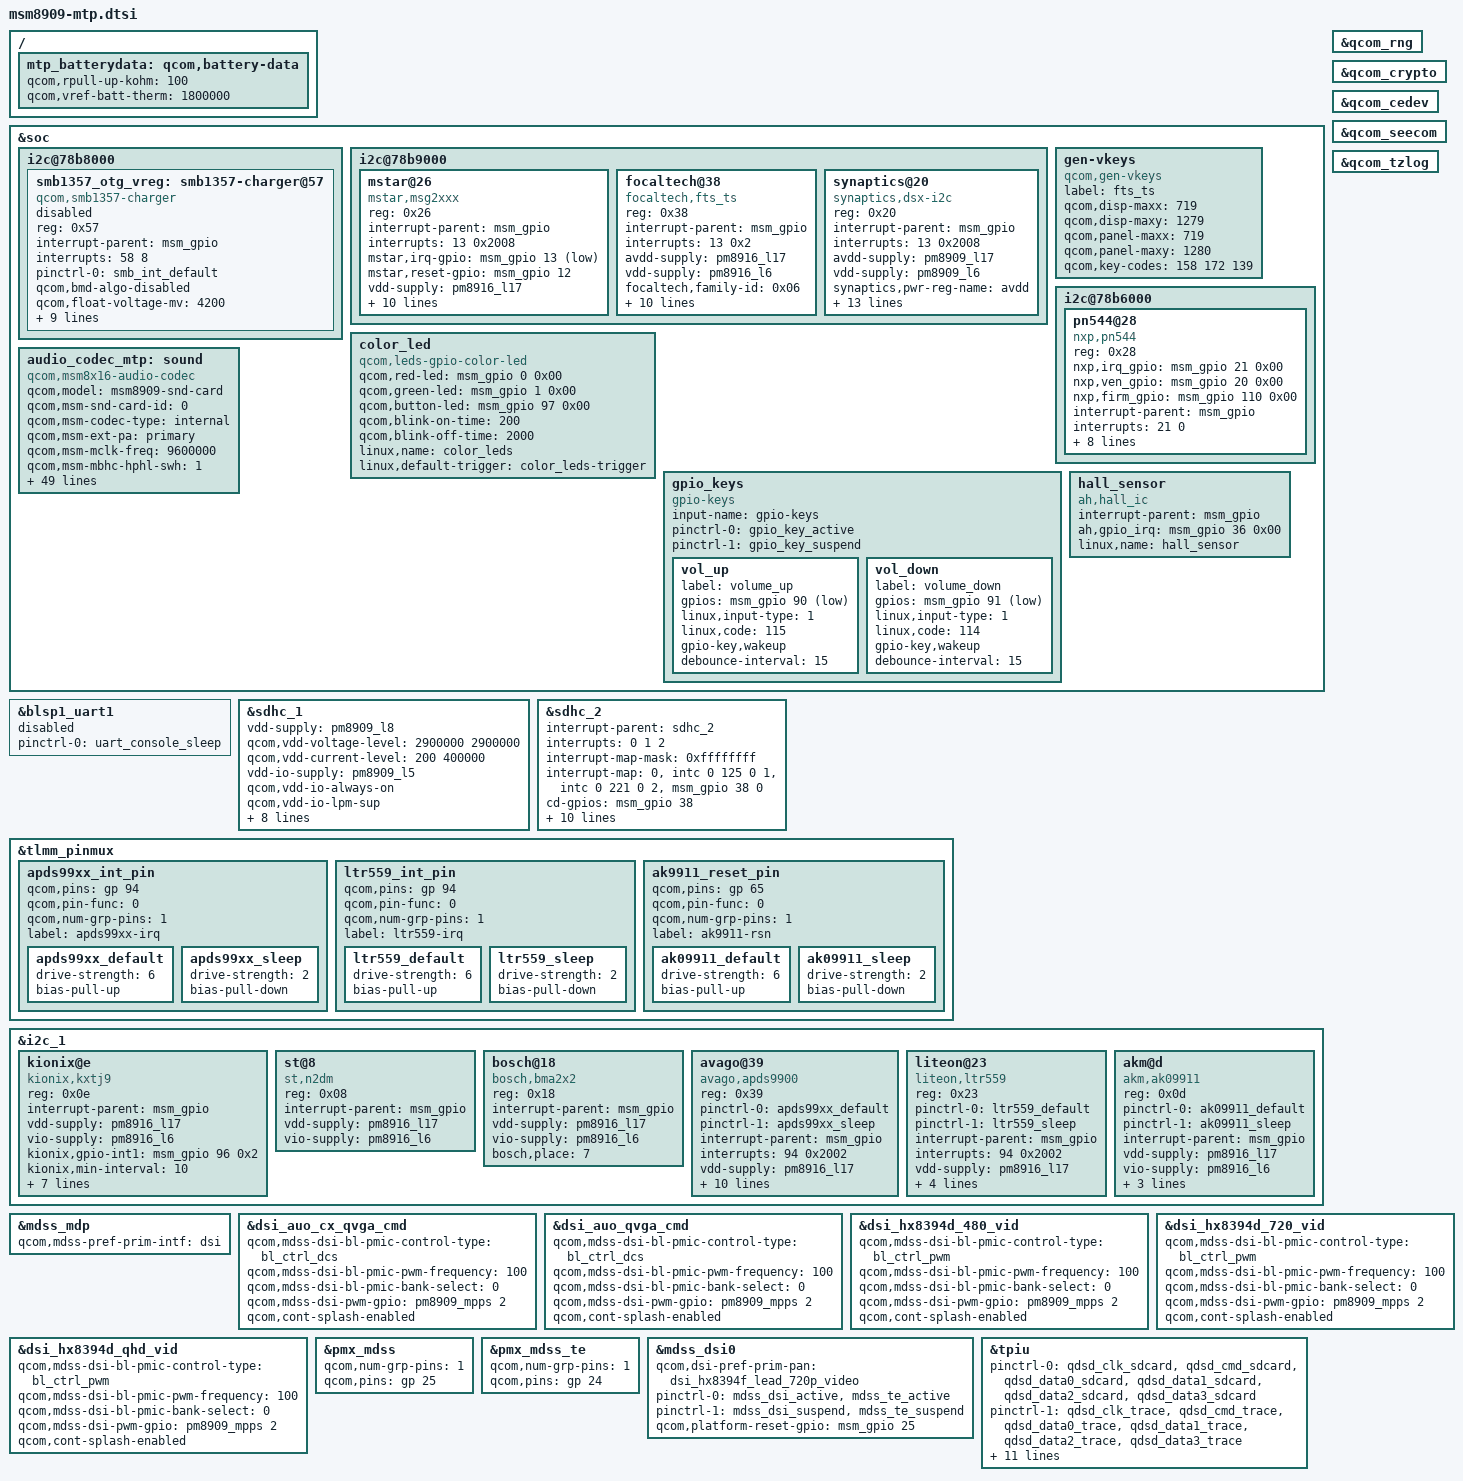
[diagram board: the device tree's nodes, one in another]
/* Copyright (c) 2014-2015, The Linux Foundation. All rights reserved.
 *
 * This program is free software; you can redistribute it and/or modify
 * it under the terms of the GNU General Public License version 2 and
 * only version 2 as published by the Free Software Foundation.
 *
 * This program is distributed in the hope that it will be useful,
 * but WITHOUT ANY WARRANTY; without even the implied warranty of
 * MERCHANTABILITY or FITNESS FOR A PARTICULAR PURPOSE.  See the
 * GNU General Public License for more details.
 */

#include "msm8909.dtsi"
#include "msm8909-pinctrl.dtsi"
#include "msm8909-camera-sensor-mtp.dtsi"
#include "msm8909-pm8916.dtsi"


&soc {
	/*
	 * DT node to add support for SMB135x charger and integrate
	 * with VM-BMS.
	 */
	i2c@78b8000 {
		smb1357_otg_vreg: smb1357-charger@57 {
			compatible = "qcom,smb1357-charger";
			reg = <0x57>;
			interrupt-parent = <&msm_gpio>;
			interrupts = <58 8>;
			pinctrl-names = "default";
			pinctrl-0 = <&smb_int_default>;

			qcom,bmd-algo-disabled;
			qcom,float-voltage-mv = <4200>;
			qcom,charging-timeout = <1536>;
			qcom,recharge-thresh-mv = <100>;
			regulator-name = "smb1357_otg_vreg";
			qcom,soft-vfloat-comp-disabled;
			qcom,thermal-mitigation = <1500 700 600 0>;

			qcom,bms-psy-name = "bms";

			/*
			 * Disable SMB1357 based charging termination as BMS
			 * controls charging.
			 */
			qcom,iterm-disabled;

			/*
			 * Disable charge inhibit feature to start chargin on
			 * charger insertion independent of battery voltage.
			 */
			qcom,inhibit-disabled;

			/* BMS is controlling charging/re-charge */
			qcom,bms-controlled-charging;

			/*
			 * To enable charger node:
			 * set status = "ok" and
			 * add 'qcom,use-external-charger' to pm8909_chg node
			 */
			status = "disabled";
		};
	};

	i2c@78b9000 { /* BLSP1 QUP5 */
	    mstar@26 { /*ZTE_MODIFY */
			compatible = "mstar,msg2xxx";
			reg = <0x26>;
			interrupt-parent = <&msm_gpio>;
			interrupts = <13 0x2008>;
			mstar,irq-gpio = <&msm_gpio 13 0x00000001>;
			mstar,reset-gpio = <&msm_gpio 12 0x0>;
			vdd-supply = <&pm8916_l17>;
			vcc_i2c-supply = <&pm8916_l6>;
			mstar,display-coords = <0 0 480 854>;
			pinctrl-names = "pmx_ts_active","pmx_ts_suspend","pmx_ts_release";
			pinctrl-0 = <&ts_int_active &ts_reset_active>;
			pinctrl-1 = <&ts_int_suspend &ts_reset_suspend>;
			pinctrl-2 = <&ts_release>;
			mstar,button-map = <158 172 139>;
			mstar,ic-type = <2>;
			mstar,num-max-touches = <5>;
			mstar,hard-reset-delay-ms = <100>;
			mstar,post-hard-reset-delay-ms = <100>;
		};
		focaltech@38{
			compatible = "focaltech,fts_ts";
			reg = <0x38>;
			interrupt-parent = <&msm_gpio>;
			interrupts = <13 0x2>;
			avdd-supply = <&pm8916_l17>;
			vdd-supply = <&pm8916_l6>;
			focaltech,family-id = <0x06>;
			focaltech,reset-gpio = <&msm_gpio 12 0x00>;
			focaltech,irq-gpio = <&msm_gpio 13 0x00>;
			focaltech,display-coords = <0 0 720 1280>;
			focaltech,panel-coords = <0 0 720 1280>;
			focaltech,button-map= <158 172 139>;
			focaltech,hard-reset-delay-ms = <20>;
			focaltech,soft-reset-delay-ms = <150>;
			focaltech,num-max-touches = <10>;
			focaltech,no-force-update;
			focaltech,i2c-pull-up;
		};

		synaptics@20 {
			compatible = "synaptics,dsx-i2c";
			reg = <0x20>;
			interrupt-parent = <&msm_gpio>;
			interrupts = <13 0x2008>;
			avdd-supply = <&pm8909_l17>;
			vdd-supply = <&pm8909_l6>;
			synaptics,pwr-reg-name = "avdd";
			synaptics,bus-reg-name = "vdd";
			synaptics,irq-gpio = <&msm_gpio 13 0x2008>;
			synaptics,reset-gpio = <&msm_gpio 12 0x0>;
			synaptics,irq-on-state = <0>;
			synaptics,irq-flags = <0x2008>; /* IRQF_ONESHOT | IRQF_TRIGGER_LOW */
			synaptics,power-delay-ms = <200>;
			synaptics,reset-delay-ms = <200>;
			synaptics,reset-on-state = <0>;
			synaptics,reset-active-ms = <20>;
			synaptics,display-coords = <0 0 719 1279>;
			synaptics,panel-coords = <0 0 719 1280>;
			synaptics,button-map = <139 172 158>;
			/* uncomment and update line below as appropriate if there are 0D buttons */
			synaptics,cap-button-codes = <139 172 158>;
			/* uncomment and update lines below as appropriate if there are virtual buttons */
			/* synaptics,vir-button-codes = <102 100 900 100 60 158 300 900 100 60>; */
			/* synaptics,max-y-for-2d = <800>; */
		};
	};

	gen-vkeys {
		compatible = "qcom,gen-vkeys";
		label = "synaptics_dsx";
		qcom,disp-maxx = <719>;
		qcom,disp-maxy = <1279>;
		qcom,panel-maxx = <719>;
		qcom,panel-maxy = <1280>;
		qcom,key-codes = <158 172 139>;
	};
    gen-vkeys {
		compatible = "qcom,gen-vkeys";
		label = "fts_ts";
		qcom,disp-maxx = <719>;
		qcom,disp-maxy = <1279>;
		qcom,panel-maxx = <719>;
		qcom,panel-maxy = <1280>;
		qcom,key-codes = <158 172 139>;
	};

	i2c@78b6000 { /* BLSP1 QUP2 */
	//	nfc-nci@e {
	//		compatible = "qcom,nfc-nci";
	//		reg = <0x0e>;
	//		qcom,irq-gpio = <&msm_gpio 21 0x00>;
	//		qcom,dis-gpio = <&msm_gpio 20 0x00>;
	//		qcom,clk-src = "BBCLK2";
	//		interrupt-parent = <&msm_gpio>;
	//		interrupts = <21 0>;
	//		interrupt-names = "nfc_irq";
	//		pinctrl-names = "nfc_active","nfc_suspend";
	//		pinctrl-0 = <&nfc_int_active &nfc_disable_active>;
	//		pinctrl-1 = <&nfc_int_suspend &nfc_disable_suspend>;
	//		qcom,clk-gpio = <&pm8909_gpios 2 0>;
	//		clocks = <&clock_rpm clk_bb_clk2_pin>;
	//		clock-names = "ref_clk";
	//	};
		pn544@28 {
			compatible = "nxp,pn544";
			reg = <0x28>;
			nxp,irq_gpio = <&msm_gpio 21 0x00>;
			nxp,ven_gpio = <&msm_gpio 20 0x00>;
			nxp,firm_gpio = <&msm_gpio 110 0x00>;
			interrupt-parent = <&msm_gpio>;
			interrupts = <21 0>;
			interrupt-names = "nfc_irq";
			pinctrl-names = "nfc_active","nfc_suspend";
			pinctrl-0 = <&nfc_int_active &nfc_disable_active &nfc_download_active>;
			pinctrl-1 = <&nfc_int_suspend &nfc_disable_suspend &nfc_download_suspend>;
			nxp,clk-src = "BBCLK2";
			nxp,clk-gpio = <&pm8916_gpios 2 0>;
			clocks = <&clock_rpm clk_bb_clk2_pin>;
			clock-names = "ref_clk";
			vdd-supply = <&pm8916_l5>;
		};
	};
/*chenyingfang 20150924 for color_led,start*/
	color_led {
		compatible = "qcom,leds-gpio-color-led";
		status = "okay";
		qcom,red-led = <&msm_gpio 0 0x00>;
		qcom,green-led = <&msm_gpio 1 0x00>;
		qcom,button-led = <&msm_gpio 97 0x00>;
		qcom,blink-on-time = <200>;
		qcom,blink-off-time = <2000>;
		linux,name = "color_leds";
		linux,default-trigger = "color_leds-trigger";
	};
/*chenyingfang 20150924 for color_led,end*/
	gpio_keys {
		compatible = "gpio-keys";
		input-name = "gpio-keys";
		pinctrl-names = "tlmm_gpio_key_active","tlmm_gpio_key_suspend";
		pinctrl-0 = <&gpio_key_active>;
		pinctrl-1 = <&gpio_key_suspend>;

        /* ZTE_MODIFY start by dingli10091962
		camera_focus {
			label = "camera_focus";
			gpios = <&msm_gpio 91 0x1>;
			linux,input-type = <1>;
			linux,code = <0x210>;
			gpio-key,wakeup;
			debounce-interval = <15>;
		};

		camera_snapshot {
			label = "camera_snapshot";
			gpios = <&msm_gpio 92 0x1>;
			linux,input-type = <1>;
			linux,code = <0x2fe>;
			gpio-key,wakeup;
			debounce-interval = <15>;
		};
        ZTE_MODIFY end by dingli10091962 */
        
		vol_up {
			label = "volume_up";
			gpios = <&msm_gpio 90 0x1>;
			linux,input-type = <1>;
			linux,code = <115>;
			gpio-key,wakeup;
			debounce-interval = <15>;
		};

		// ZTE_MODIFY start by dingli10091962
        vol_down {
			label = "volume_down";
			gpios = <&msm_gpio 91 0x1>;
			linux,input-type = <1>;
			linux,code = <114>;
			gpio-key,wakeup;
			debounce-interval = <15>;
		};
        // ZTE_MODIFY end by dingli10091962        
	};

	audio_codec_mtp: sound {
		compatible = "qcom,msm8x16-audio-codec";
		qcom,model = "msm8909-snd-card";
		qcom,msm-snd-card-id = <0>;
		qcom,msm-codec-type = "internal";
		qcom,msm-ext-pa = "primary";
		qcom,msm-mclk-freq = <9600000>;
		qcom,msm-mbhc-hphl-swh = <1>;
		qcom,msm-mbhc-gnd-swh = <1>;
		qcom,msm-hs-micbias-type = "internal";
		//qcom,msm-micbias1-ext-cap;
		qcom,audio-routing =
			"RX_BIAS", "MCLK",
			"SPK_RX_BIAS", "MCLK",
			"INT_LDO_H", "MCLK",
			"MIC BIAS External", "Handset Mic",
			"MIC BIAS Internal2", "Headset Mic",
			"MIC BIAS External", "Secondary Mic",
			"AMIC1", "MIC BIAS External",
			"AMIC2", "MIC BIAS Internal2",
			"AMIC3", "MIC BIAS External";
		pinctrl-names = "cdc_lines_act",
				"cdc_lines_sus",
				"cross_conn_det_act",
				"cross_conn_det_sus";
		pinctrl-0 = <&cdc_pdm_lines_act>;
		pinctrl-1 = <&cdc_pdm_lines_sus>;
		pinctrl-2 = <&cross_conn_det_act>;
		pinctrl-3 = <&cross_conn_det_sus>;
		qcom,msm-spk-ext-pa = <&msm_gpio 95 0>;
		//qcom,cdc-us-euro-gpios = <&msm_gpio 97 0>;
		asoc-platform = <&pcm0>, <&pcm1>, <&voip>, <&voice>,
				<&loopback>, <&compress>, <&hostless>,
				<&afe>, <&lsm>, <&routing>, <&lpa>,
				<&voice_svc>;
		asoc-platform-names = "msm-pcm-dsp.0", "msm-pcm-dsp.1",
				"msm-voip-dsp", "msm-pcm-voice", "msm-pcm-loopback",
				"msm-compress-dsp", "msm-pcm-hostless", "msm-pcm-afe",
				"msm-lsm-client", "msm-pcm-routing", "msm-pcm-lpa",
				"msm-voice-svc";
		asoc-cpu = <&dai_pri_auxpcm>, <&dai_hdmi>,
				<&dai_mi2s0>, <&dai_mi2s1>, <&dai_mi2s2>, <&dai_mi2s3>,
				<&sb_0_rx>, <&sb_0_tx>, <&sb_1_rx>, <&sb_1_tx>,
				<&sb_3_rx>, <&sb_3_tx>, <&sb_4_rx>, <&sb_4_tx>,
				<&bt_sco_rx>, <&bt_sco_tx>,<&bt_a2dp_rx>,
                                <&int_fm_rx>, <&int_fm_tx>,
				<&afe_pcm_rx>, <&afe_pcm_tx>, <&afe_proxy_rx>, <&afe_proxy_tx>,
				<&incall_record_rx>, <&incall_record_tx>, <&incall_music_rx>,
				<&incall_music_2_rx>;
		asoc-cpu-names = "msm-dai-q6-auxpcm.1", "msm-dai-q6-hdmi.8",
				"msm-dai-q6-mi2s.0", "msm-dai-q6-mi2s.1",
				"msm-dai-q6-mi2s.2", "msm-dai-q6-mi2s.3",
				"msm-dai-q6-dev.16384", "msm-dai-q6-dev.16385",
				"msm-dai-q6-dev.16386", "msm-dai-q6-dev.16387",
				"msm-dai-q6-dev.16390", "msm-dai-q6-dev.16391",
				"msm-dai-q6-dev.16392", "msm-dai-q6-dev.16393",
				"msm-dai-q6-dev.12288", "msm-dai-q6-dev.12289",
				"msm-dai-q6-dev.12290", "msm-dai-q6-dev.12292",
                                "msm-dai-q6-dev.12293", "msm-dai-q6-dev.224",
				"msm-dai-q6-dev.225", "msm-dai-q6-dev.241",
				"msm-dai-q6-dev.240", "msm-dai-q6-dev.32771",
				"msm-dai-q6-dev.32772", "msm-dai-q6-dev.32773",
                                "msm-dai-q6-dev.32770";
		asoc-codec = <&stub_codec>, <&pm8909_conga_dig>;
		asoc-codec-names = "msm-stub-codec.1", "tombak_codec";
	};
};

&blsp1_uart1 {
	status = "disabled";
	pinctrl-names = "default";
	pinctrl-0 = <&uart_console_sleep>;
};

/ {
	mtp_batterydata: qcom,battery-data {
		qcom,rpull-up-kohm = <100>;
		qcom,vref-batt-therm = <1800000>;

		#include "batterydata-palladium.dtsi"
	};
};

&qcom_rng {
	status = "okay";
};

&qcom_crypto {
	status = "okay";
};

&qcom_cedev {
	status = "okay";
};

&qcom_seecom {
	status = "okay";
};

&qcom_tzlog {
	status = "okay";
};

&sdhc_1 {
	vdd-supply = <&pm8909_l8>;
	qcom,vdd-voltage-level = <2900000 2900000>;
	qcom,vdd-current-level = <200 400000>;

	vdd-io-supply = <&pm8909_l5>;
	qcom,vdd-io-always-on;
	qcom,vdd-io-lpm-sup;
	qcom,vdd-io-voltage-level = <1800000 1800000>;
	qcom,vdd-io-current-level = <200 60000>;

	pinctrl-names = "active", "sleep";
	pinctrl-0 = <&sdc1_clk_on &sdc1_cmd_on &sdc1_data_on>;
	pinctrl-1 = <&sdc1_clk_off &sdc1_cmd_off &sdc1_data_off>;

	qcom,bus-speed-mode = "HS200_1p8v", "DDR_1p8v";
	qcom,nonremovable;

	status = "ok";
};

&sdhc_2 {
	 #address-cells = <0>;
	interrupt-parent = <&sdhc_2>;
	interrupts = <0 1 2>;
	#interrupt-cells = <1>;
	interrupt-map-mask = <0xffffffff>;
	interrupt-map = <0 &intc 0 125 0
			1 &intc 0 221 0
			2 &msm_gpio 38 0>;
	interrupt-names = "hc_irq", "pwr_irq", "status_irq";
	// ZTE_MODIFY start by xiongping10053992 	
	cd-gpios = <&msm_gpio 38 0x0>;
	// ZTE_MODIFY end by xiongping10053992 	

	vdd-supply = <&pm8909_l11>;
	qcom,vdd-voltage-level = <1800000 2950000>;
	qcom,vdd-current-level = <15000 400000>;

	vdd-io-supply = <&pm8909_l12>;
	qcom,vdd-io-voltage-level = <1800000 2950000>;
	qcom,vdd-io-current-level = <200 50000>;

	pinctrl-names = "active", "sleep";
	pinctrl-0 = <&sdc2_clk_on &sdc2_cmd_on &sdc2_data_on &sdc2_cd_on>;
	pinctrl-1 = <&sdc2_clk_off &sdc2_cmd_off &sdc2_data_off &sdc2_cd_off>;

	status = "ok";
};

&tlmm_pinmux {
	apds99xx_int_pin {
		qcom,pins = <&gp 94>;
		qcom,pin-func = <0>;
		qcom,num-grp-pins = <1>;
		label = "apds99xx-irq";
		apds99xx_default: apds99xx_default {
			drive-strength = <6>;
			bias-pull-up;
		};
		apds99xx_sleep: apds99xx_sleep {
			drive-strength = <2>;
			bias-pull-down;
		};
	};

	    ltr559_int_pin {
		qcom,pins = <&gp 94>;
		qcom,pin-func = <0>;
		qcom,num-grp-pins = <1>;
		    label = "ltr559-irq";
		    ltr559_default: ltr559_default {
			drive-strength = <6>;
			bias-pull-up;
		};
		    ltr559_sleep: ltr559_sleep {
			drive-strength = <2>;
			bias-pull-down;
		};
	};
	ak9911_reset_pin {
		qcom,pins = <&gp 65>;
		qcom,pin-func = <0>;
		qcom,num-grp-pins = <1>;
		label = "ak9911-rsn";
		ak09911_default: ak09911_default {
			drive-strength = <6>;
			bias-pull-up;
		};
		ak09911_sleep: ak09911_sleep {
			drive-strength = <2>;
			bias-pull-down;
		};
	};
};

&i2c_1 { /* BLSP1 QUP1 */
	kionix@e {
		compatible = "kionix,kxtj9";
		reg = <0x0e>;
		interrupt-parent = <&msm_gpio>;
		vdd-supply = <&pm8916_l17>;
		vio-supply = <&pm8916_l6>;
		kionix,gpio-int1 = <&msm_gpio 96 0x2>;
		kionix,min-interval = <10>;
		kionix,init-interval = <100>;
		kionix,axis-map-x = <1>;
		kionix,axis-map-y = <0>;
		kionix,axis-map-z = <2>;
		kionix,g-range = <2>;
		kionix,res-12bit;
		//kionix,negate-x; 
		//kionix,negate-y;
		kionix,negate-z;
		}; 

	st@8 {
		compatible = "st,n2dm";
		reg = <0x08>;
		interrupt-parent = <&msm_gpio>;
		vdd-supply = <&pm8916_l17>;
		vio-supply = <&pm8916_l6>;
	};

	bosch@18 {
		compatible = "bosch,bma2x2";
		reg = <0x18>;
		interrupt-parent = <&msm_gpio>;
		vdd-supply = <&pm8916_l17>;
		vio-supply = <&pm8916_l6>;	
		bosch,place	 = <7>;
	};	

	avago@39 { /* Ambient light and proximity sensor */
		compatible = "avago,apds9900";
		reg = <0x39>;
		pinctrl-names = "default","sleep";
		pinctrl-0 = <&apds99xx_default>;
		pinctrl-1 = <&apds99xx_sleep>;
		interrupt-parent = <&msm_gpio>;
		interrupts = <94 0x2002>;
		vdd-supply = <&pm8916_l17>;
		vio-supply = <&pm8916_l6>;
		avago,irq-gpio = <&msm_gpio 94 0x2002>;
		//avago,ps-threshold = <600>;
		//avago,ps-hysteresis-threshold = <500>;
		avago,ps-threshold = <500>;
		avago,ps-hysteresis-threshold = <400>;
		avago,ps-pulse = <25>;
		avago,ps-pgain = <4>;
		avago,als-B = <186>;
		avago,als-C = <75>;
		avago,als-D = <129>;
		avago,ga-value = <256>;
	};

	    liteon@23 {
		    compatible = "liteon,ltr559";
		    reg = <0x23>;
		    pinctrl-names = "default","sleep";
		    pinctrl-0 = <&ltr559_default>;
		    pinctrl-1 = <&ltr559_sleep>;
			interrupt-parent = <&msm_gpio>;
		    interrupts = <94 0x2002>;
			vdd-supply = <&pm8916_l17>;
			vio-supply = <&pm8916_l6>;
		    liteon,intr = <&msm_gpio 94 0x2002>;
		    liteon,highthr = <300>;
		    liteon,lowthr = <200>;
	};


	akm@d {
		compatible = "akm,ak09911";
		reg = <0x0d>;	
		pinctrl-names = "ak09911_default", "ak09911_sleep";
		pinctrl-0 = <&ak09911_default>;
		pinctrl-1 = <&ak09911_sleep>;
		interrupt-parent = <&msm_gpio>;
		vdd-supply = <&pm8916_l17>;
		vio-supply = <&pm8916_l6>;
		akm,layout = <6>;
		akm,auto-report;
		akm,gpio_rstn = <&msm_gpio 65 0x00>;
	};
};

#include "dsi-panel-auo-qvga-cmd.dtsi"
#include "dsi-panel-auo-cx-qvga-cmd.dtsi"
#include "dsi-panel-hx8394d-480p-video.dtsi"
#include "dsi-panel-hx8394d-720p-video.dtsi"
#include "dsi-panel-hx8394d-qhd-video.dtsi"
#include "dsi-panel-hx8394f-lead-720p-video.dtsi"
#include "dsi-panel-hx8394f-yassy-720p-video.dtsi"
#include "dsi-panel-hx8394f-jdf-720p-video.dtsi"
#include "dsi-panel-nt35521-dijing-720p-video.dtsi"
&mdss_mdp {
	qcom,mdss-pref-prim-intf = "dsi";
};

&dsi_auo_cx_qvga_cmd {
        qcom,mdss-dsi-bl-pmic-control-type = "bl_ctrl_dcs";
        qcom,mdss-dsi-bl-pmic-pwm-frequency = <100>;
        qcom,mdss-dsi-bl-pmic-bank-select = <0>;
        qcom,mdss-dsi-pwm-gpio = <&pm8909_mpps 2 0>;
        qcom,cont-splash-enabled;
};

&dsi_auo_qvga_cmd {
        qcom,mdss-dsi-bl-pmic-control-type = "bl_ctrl_dcs";
        qcom,mdss-dsi-bl-pmic-pwm-frequency = <100>;
        qcom,mdss-dsi-bl-pmic-bank-select = <0>;
        qcom,mdss-dsi-pwm-gpio = <&pm8909_mpps 2 0>;
        qcom,cont-splash-enabled;
};

&dsi_hx8394d_480_vid {
        qcom,mdss-dsi-bl-pmic-control-type = "bl_ctrl_pwm";
        qcom,mdss-dsi-bl-pmic-pwm-frequency = <100>;
        qcom,mdss-dsi-bl-pmic-bank-select = <0>;
        qcom,mdss-dsi-pwm-gpio = <&pm8909_mpps 2 0>;
        qcom,cont-splash-enabled;
};

&dsi_hx8394d_720_vid {
	qcom,mdss-dsi-bl-pmic-control-type = "bl_ctrl_pwm";
	qcom,mdss-dsi-bl-pmic-pwm-frequency = <100>;
	qcom,mdss-dsi-bl-pmic-bank-select = <0>;
	qcom,mdss-dsi-pwm-gpio = <&pm8909_mpps 2 0>;
	qcom,cont-splash-enabled;
};

&dsi_hx8394d_qhd_vid {
	qcom,mdss-dsi-bl-pmic-control-type = "bl_ctrl_pwm";
	qcom,mdss-dsi-bl-pmic-pwm-frequency = <100>;
	qcom,mdss-dsi-bl-pmic-bank-select = <0>;
	qcom,mdss-dsi-pwm-gpio = <&pm8909_mpps 2 0>;
	qcom,cont-splash-enabled;
};

&pmx_mdss {
	//qcom,num-grp-pins = <2>;
	//qcom,pins = <&gp 25>, <&gp 37>;
	qcom,num-grp-pins = <1>;
	qcom,pins = <&gp 25>;
};

&pmx_mdss_te {
	qcom,num-grp-pins = <1>;
	qcom,pins = <&gp 24>;
};

&mdss_dsi0 {
	qcom,dsi-pref-prim-pan = <&dsi_hx8394f_lead_720p_video>;
	pinctrl-names = "mdss_default", "mdss_sleep";
	pinctrl-0 = <&mdss_dsi_active &mdss_te_active>;
	pinctrl-1 = <&mdss_dsi_suspend &mdss_te_suspend>;

	qcom,platform-reset-gpio = <&msm_gpio 25 0>;
	//qcom,platform-bklight-en-gpio = <&msm_gpio 37 0>;//modify by yujianhua no useful gpio
};

/* CoreSight */
&tpiu {
	pinctrl-names = "sdcard", "trace", "swduart",
			"swdtrc", "jtag", "spmi";
	/* NIDnT */
	pinctrl-0 = <&qdsd_clk_sdcard &qdsd_cmd_sdcard
		     &qdsd_data0_sdcard &qdsd_data1_sdcard
		     &qdsd_data2_sdcard &qdsd_data3_sdcard>;
	pinctrl-1 = <&qdsd_clk_trace &qdsd_cmd_trace
		     &qdsd_data0_trace &qdsd_data1_trace
		     &qdsd_data2_trace &qdsd_data3_trace>;
	pinctrl-2 = <&qdsd_cmd_swduart &qdsd_data0_swduart
		     &qdsd_data1_swduart &qdsd_data2_swduart
		     &qdsd_data3_swduart>;
	pinctrl-3 = <&qdsd_clk_swdtrc &qdsd_cmd_swdtrc
		     &qdsd_data0_swdtrc &qdsd_data1_swdtrc
		     &qdsd_data2_swdtrc &qdsd_data3_swdtrc>;
	pinctrl-4 = <&qdsd_cmd_jtag &qdsd_data0_jtag
		     &qdsd_data1_jtag &qdsd_data2_jtag
		     &qdsd_data3_jtag>;
	pinctrl-5 = <&qdsd_clk_spmi &qdsd_cmd_spmi
		     &qdsd_data0_spmi &qdsd_data3_spmi>;
};

&soc {
	hall_sensor {
		compatible = "ah,hall_ic";
		interrupt-parent = <&msm_gpio>;			
		ah,gpio_irq = <&msm_gpio 36 0x00>;
		linux,name = "hall_sensor";	
	};
		    
};
